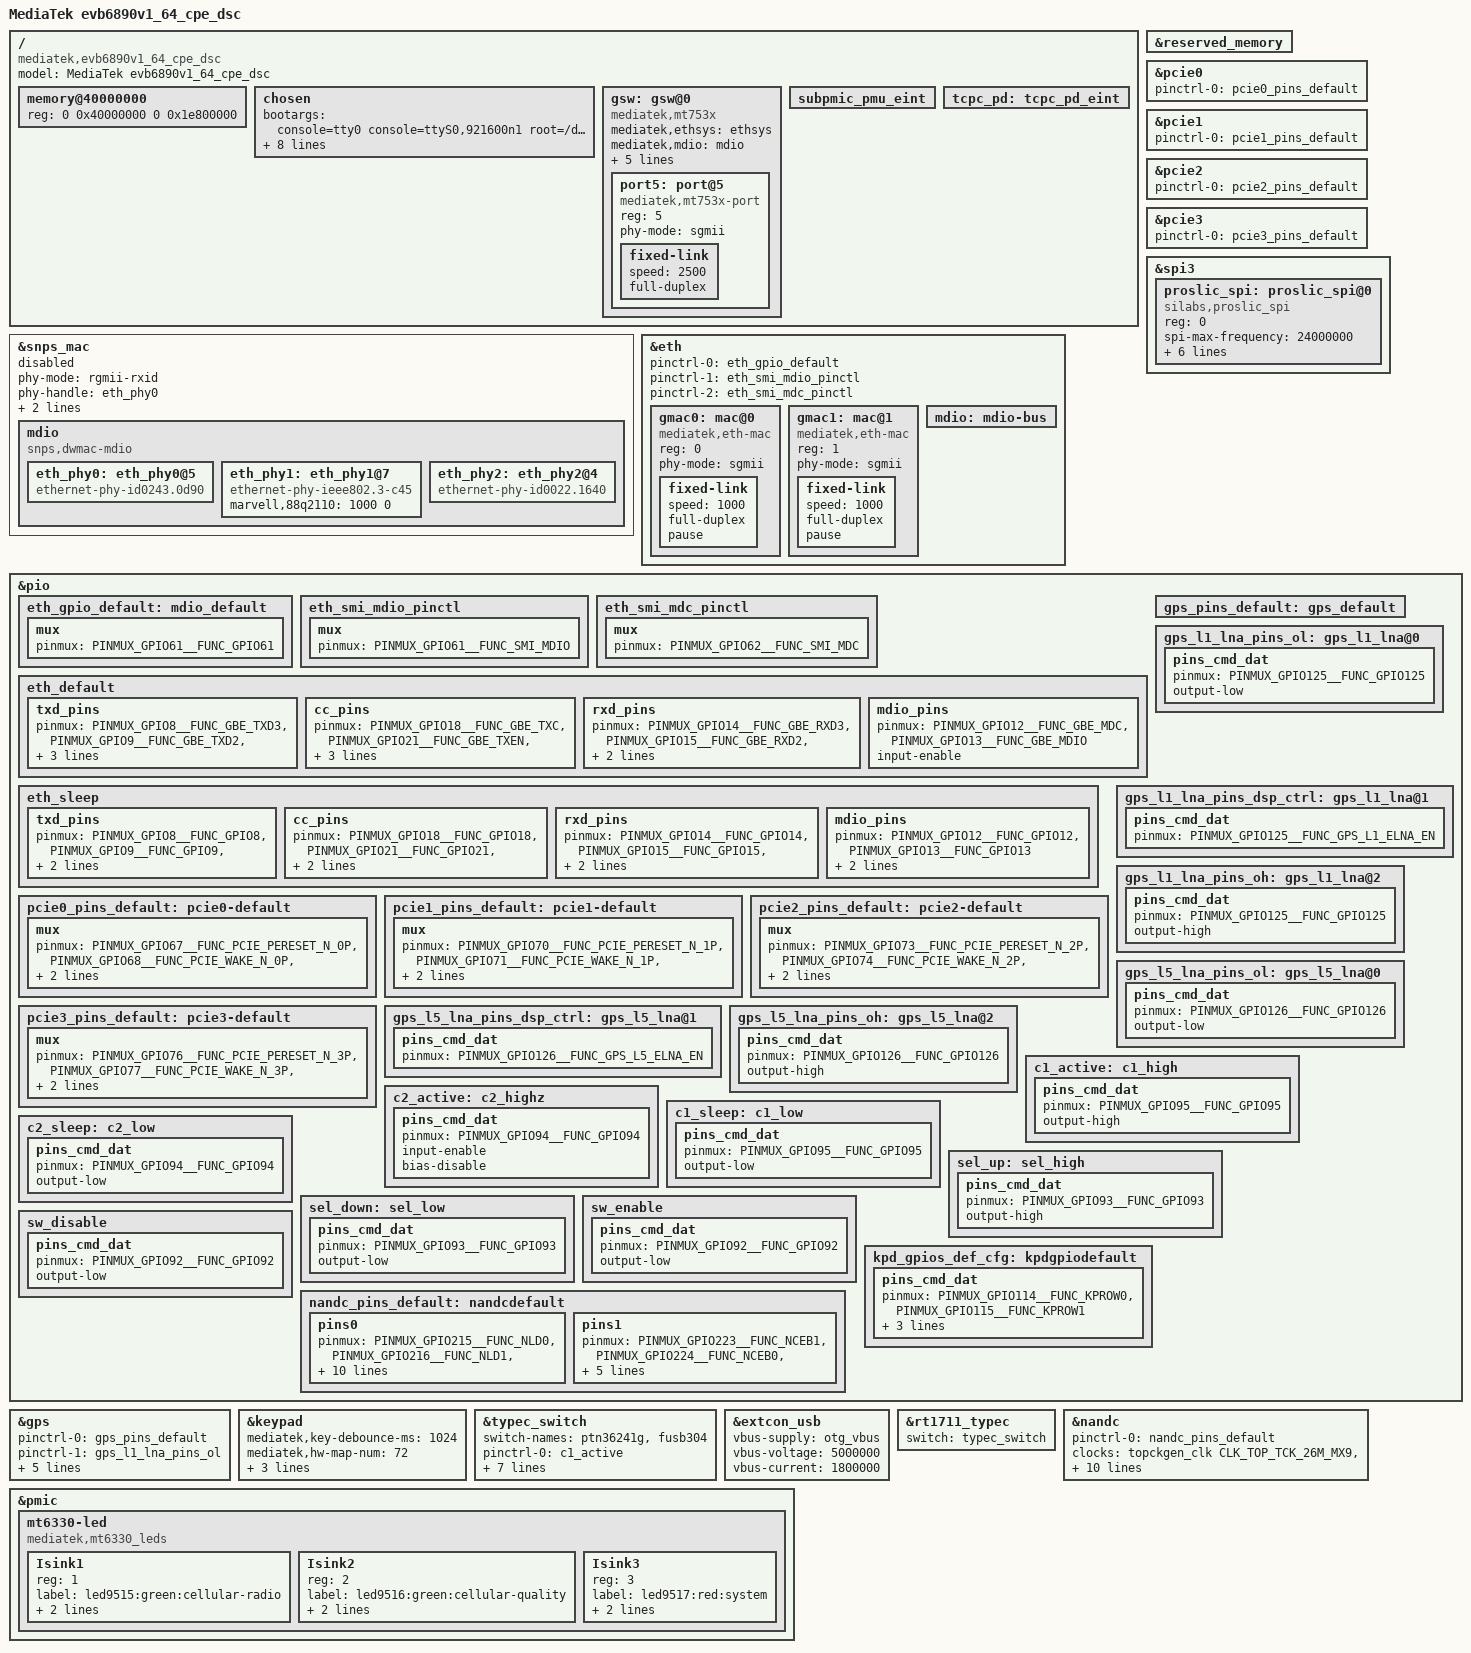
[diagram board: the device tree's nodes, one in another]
// SPDX-License-Identifier: GPL-2.0
/*
 * Copyright (c) 2019 MediaTek Inc.
 */

/dts-v1/;
#include <dt-bindings/interrupt-controller/irq.h>
#include <dt-bindings/interrupt-controller/arm-gic.h>
#include "mt6890.dtsi"
#include "tcpc_config.dtsi"
#include "rt9467.dtsi"

&reserved_memory {
};

/ {
	model = "MediaTek evb6890v1_64_cpe_dsc";
	compatible = "mediatek,evb6890v1_64_cpe_dsc", "mediatek,mt6890";

	memory@40000000 {
		device_type = "memory";
		reg = <0 0x40000000 0 0x1e800000>;
	};

	chosen {
		bootargs = "console=tty0 console=ttyS0,921600n1 \
		root=/dev/ubiblock0_0 rootfstype=squashfs ubi.mtd=28 \
		init=/etc/preinit \
		loglevel=8 \
		androidboot.selinux=permissive androidboot.hardware=mt6890 \
		initcall_debug=1";

		atag,videolfb-fb_base_l = <0x7e605000>;
		atag,videolfb-fb_base_h = <0x0>;
		atag,videolfb-islcmfound = <1>;
		atag,videolfb-islcm_inited = <0>;
		atag,videolfb-fps= <6000>;
		atag,videolfb-vramSize= <0x1be0000>;
		atag,videolfb-lcmname=
			"nt35595_fhd_dsi_cmd_truly_nt50358_drv";
	};

	gsw: gsw@0 {
		compatible = "mediatek,mt753x";
		mediatek,ethsys = <&ethsys>;
		#address-cells = <1>;
		#size-cells = <0>;
	};

	subpmic_pmu_eint: subpmic_pmu_eint {
	};

	tcpc_pd: tcpc_pd_eint {
	};
};

&snps_mac {
	phy-mode ="rgmii-rxid";
	phy-handle = <&eth_phy0>;
	status = "disable";
	pinctrl-names = "default", "sleep";
	pinctrl-0 = <&eth_default>;
	pinctrl-1 = <&eth_sleep>;
	mdio {
		compatible = "snps,dwmac-mdio";
		#address-cells = <1>;
		#size-cells = <0>;
		eth_phy0: eth_phy0@5 {
			compatible = "ethernet-phy-id0243.0d90";
		};
		eth_phy1: eth_phy1@7 {
			compatible = "ethernet-phy-ieee802.3-c45";
			marvell,88q2110 = <1000 0>;
		};
		eth_phy2: eth_phy2@4 {
			compatible = "ethernet-phy-id0022.1640";
		};
	};
};


&eth {
	pinctrl-names = "eth_gpio_default",
		"eth_smi_mdio_pinctl",
		"eth_smi_mdc_pinctl";
	pinctrl-0 = <&eth_gpio_default>;
	pinctrl-1 = <&eth_smi_mdio_pinctl>;
	pinctrl-2 = <&eth_smi_mdc_pinctl>;
	status = "okay";
	gmac0: mac@0 {
		compatible = "mediatek,eth-mac";
		reg = <0>;
		phy-mode = "sgmii";
		fixed-link {
			speed = <1000>;
			full-duplex;
			pause;
		};
	};
	gmac1: mac@1 {
		compatible = "mediatek,eth-mac";
		reg = <1>;
		phy-mode = "sgmii";
		fixed-link {
			speed = <1000>;
			full-duplex;
			pause;
		};
	};
	mdio: mdio-bus {
		#address-cells = <1>;
		#size-cells = <0>;
	};
};

&gsw {
	mediatek,mdio = <&mdio>;
	mediatek,portmap = "llllw";
	mediatek,mdio_master_pinmux = <0>;
	reset-gpios = <&pio 66 0>;
	interrupt-parent = <&pio>;
	interrupts = <65 IRQ_TYPE_LEVEL_HIGH>;

	status = "okay";

	port5: port@5 {
		compatible = "mediatek,mt753x-port";
		reg = <5>;
		phy-mode = "sgmii";
		fixed-link {
			speed = <2500>;
			full-duplex;
		};
	};
};

&pcie0 {
	pinctrl-names = "default";
	pinctrl-0 = <&pcie0_pins_default>;
	status = "okay";
};

&pcie1 {
	pinctrl-names = "default";
	pinctrl-0 = <&pcie1_pins_default>;
	status = "okay";
};

&pcie2 {
	pinctrl-names = "default";
	pinctrl-0 = <&pcie2_pins_default>;
	status = "okay";
};

&pcie3 {
	pinctrl-names = "default";
	pinctrl-0 = <&pcie3_pins_default>;
	status = "okay";
};

/*
&odm {
	vibrator0:vibrator@0 {
		compatible = "mediatek,vibrator";
		vib_timer = <25>;
		vib_limit = <9>;
		vib_vol= <9>;
	};
};*/

/* DISPSYS GPIO standardization */
#if 0
&pio {
	mtkfb_pins_lcd_bias_enp1: lcd_bias_enp1_gpio {
		pins_cmd_dat {
			pinmux = <PINMUX_GPIO28__FUNC_GPIO28>;
			slew-rate = <1>;
			output-high;
		};
	};

	mtkfb_pins_lcd_bias_enp0: lcd_bias_enp0_gpio {
		pins_cmd_dat {
			pinmux = <PINMUX_GPIO28__FUNC_GPIO28>;
			slew-rate = <1>;
			output-low;
		};
	};

	mtkfb_pins_lcd_bias_enn1: lcd_bias_enn1_gpio {
		pins_cmd_dat {
			pinmux = <PINMUX_GPIO29__FUNC_GPIO29>;
			slew-rate = <1>;
			output-high;
		};
	};

	mtkfb_pins_lcd_bias_enn0: lcd_bias_enn0_gpio {
		pins_cmd_dat {
			pinmux = <PINMUX_GPIO29__FUNC_GPIO29>;
			slew-rate = <1>;
			output-low;
		};
	};

	mtkfb_pins_lcm_rst_out1_gpio: lcm_rst_out1_gpio {
		pins_cmd_dat {
			pinmux = <PINMUX_GPIO42__FUNC_GPIO42>;
			slew-rate = <1>;
			output-high;
		};
	};

	mtkfb_pins_lcm_rst_out0_gpio: lcm_rst_out0_gpio {
		pins_cmd_dat {
			pinmux = <PINMUX_GPIO42__FUNC_GPIO42>;
			slew-rate = <1>;
			output-low;
		};
	};
	mtkfb_pins_lcm_dsi_te: lcm_dsi_te {
		pins_cmd_dat {
			pinmux = <PINMUX_GPIO41__FUNC_DSI_TE>;
		};
	};
};

&mtkfb {
	pinctrl-names = "lcd_bias_enp1_gpio", "lcd_bias_enp0_gpio",
		"lcd_bias_enn1_gpio", "lcd_bias_enn0_gpio",
		"lcm_rst_out1_gpio", "lcm_rst_out0_gpio",
		"mode_te_te";
	pinctrl-0 = <&mtkfb_pins_lcd_bias_enp1>;
	pinctrl-1 = <&mtkfb_pins_lcd_bias_enp0>;
	pinctrl-2 = <&mtkfb_pins_lcd_bias_enn1>;
	pinctrl-3 = <&mtkfb_pins_lcd_bias_enn0>;
	pinctrl-4 = <&mtkfb_pins_lcm_rst_out1_gpio>;
	pinctrl-5 = <&mtkfb_pins_lcm_rst_out0_gpio>;
	pinctrl-6 = <&mtkfb_pins_lcm_dsi_te>;
	status = "okay";
};
#endif

&spi3 {
	status = "okay";
	#address-cells=<1>;
	#size-cells=<0>;

	proslic_spi: proslic_spi@0 {
		compatible = "silabs,proslic_spi";
		reg = <0>;
		spi-max-frequency = <24000000>;
		spi-cpha = <1>;
		spi-cpol = <1>;
		channel_count = <1>;
		debug_level = <7>;       /* 1 = TRC, 2 = DBG, 4 = ERR */
		reset_gpio = <&pio 23 0>;       /* Hz */
		ig,enable-spi = <1>;                /* 1: Enable, 0: Disable */
	};
};
/* GPS GPIO standardization start */
#if 1
&pio {
	eth_gpio_default: mdio_default {
		mux {
			pinmux = <PINMUX_GPIO61__FUNC_GPIO61>;
		};
	};

	eth_smi_mdio_pinctl: eth_smi_mdio_pinctl {
		mux {
			pinmux = <PINMUX_GPIO61__FUNC_SMI_MDIO>;
		};
	};

	eth_smi_mdc_pinctl: eth_smi_mdc_pinctl {
		mux {
			pinmux = <PINMUX_GPIO62__FUNC_SMI_MDC>;
		};
	};

	eth_default: eth_default {
		txd_pins {
			pinmux = <PINMUX_GPIO8__FUNC_GBE_TXD3>,
				 <PINMUX_GPIO9__FUNC_GBE_TXD2>,
				 <PINMUX_GPIO10__FUNC_GBE_TXD1>,
				 <PINMUX_GPIO11__FUNC_GBE_TXD0>;
			drive-strength = <MTK_DRIVE_8mA>;
		};
		cc_pins {
			pinmux = <PINMUX_GPIO18__FUNC_GBE_TXC>,
				 <PINMUX_GPIO21__FUNC_GBE_TXEN>,
				 <PINMUX_GPIO20__FUNC_GBE_RXDV>,
				 <PINMUX_GPIO19__FUNC_GBE_RXC>;
			drive-strength = <MTK_DRIVE_8mA>;
		};
		rxd_pins {
			pinmux = <PINMUX_GPIO14__FUNC_GBE_RXD3>,
				 <PINMUX_GPIO15__FUNC_GBE_RXD2>,
				 <PINMUX_GPIO16__FUNC_GBE_RXD1>,
				 <PINMUX_GPIO17__FUNC_GBE_RXD0>;
		};
		mdio_pins {
			pinmux = <PINMUX_GPIO12__FUNC_GBE_MDC>,
				 <PINMUX_GPIO13__FUNC_GBE_MDIO>;
			input-enable;
		};
	};

	eth_sleep: eth_sleep {
		txd_pins {
			pinmux = <PINMUX_GPIO8__FUNC_GPIO8>,
				 <PINMUX_GPIO9__FUNC_GPIO9>,
				 <PINMUX_GPIO10__FUNC_GPIO10>,
				 <PINMUX_GPIO11__FUNC_GPIO11>;
		};
		cc_pins {
			pinmux = <PINMUX_GPIO18__FUNC_GPIO18>,
				 <PINMUX_GPIO21__FUNC_GPIO21>,
				 <PINMUX_GPIO20__FUNC_GPIO20>,
				 <PINMUX_GPIO19__FUNC_GPIO19>;
		};
		rxd_pins {
			pinmux = <PINMUX_GPIO14__FUNC_GPIO14>,
				 <PINMUX_GPIO15__FUNC_GPIO15>,
				 <PINMUX_GPIO16__FUNC_GPIO16>,
				 <PINMUX_GPIO17__FUNC_GPIO17>;
		};
		mdio_pins {
			pinmux = <PINMUX_GPIO12__FUNC_GPIO12>,
				 <PINMUX_GPIO13__FUNC_GPIO13>;
			input-disable;
			bias-disable;
		};
	};

	pcie0_pins_default: pcie0-default {
		mux {
			pinmux = <PINMUX_GPIO67__FUNC_PCIE_PERESET_N_0P>,
			         <PINMUX_GPIO68__FUNC_PCIE_WAKE_N_0P>,
				 <PINMUX_GPIO69__FUNC_PCIE_CLKREQ_N_0P>;
			bias-pull-up;
		};
	};

	pcie1_pins_default: pcie1-default {
		mux {
			pinmux = <PINMUX_GPIO70__FUNC_PCIE_PERESET_N_1P>,
			         <PINMUX_GPIO71__FUNC_PCIE_WAKE_N_1P>,
				 <PINMUX_GPIO72__FUNC_PCIE_CLKREQ_N_1P>;
			bias-pull-up;
		};
	};

	pcie2_pins_default: pcie2-default {
		mux {
			pinmux = <PINMUX_GPIO73__FUNC_PCIE_PERESET_N_2P>,
			         <PINMUX_GPIO74__FUNC_PCIE_WAKE_N_2P>,
				 <PINMUX_GPIO75__FUNC_PCIE_CLKREQ_N_2P>;
			bias-pull-up;
		};
	};

	pcie3_pins_default: pcie3-default {
		mux {
			pinmux = <PINMUX_GPIO76__FUNC_PCIE_PERESET_N_3P>,
			         <PINMUX_GPIO77__FUNC_PCIE_WAKE_N_3P>,
				 <PINMUX_GPIO78__FUNC_PCIE_CLKREQ_N_3P>;
			bias-pull-up;
		};
	};

	gps_pins_default: gps_default {
	};

	gps_l1_lna_pins_ol: gps_l1_lna@0 {
		pins_cmd_dat {
			pinmux = <PINMUX_GPIO125__FUNC_GPIO125>;
			output-low;
		};
	};
	gps_l1_lna_pins_dsp_ctrl: gps_l1_lna@1 {
		pins_cmd_dat {
			pinmux = <PINMUX_GPIO125__FUNC_GPS_L1_ELNA_EN>;
		};
	};
	gps_l1_lna_pins_oh: gps_l1_lna@2 {
		pins_cmd_dat {
			pinmux = <PINMUX_GPIO125__FUNC_GPIO125>;
			output-high;
		};
	};

	gps_l5_lna_pins_ol: gps_l5_lna@0 {
		pins_cmd_dat {
			pinmux = <PINMUX_GPIO126__FUNC_GPIO126>;
			output-low;
		};
	};
	gps_l5_lna_pins_dsp_ctrl: gps_l5_lna@1 {
		pins_cmd_dat {
			pinmux = <PINMUX_GPIO126__FUNC_GPS_L5_ELNA_EN>;
		};
	};
	gps_l5_lna_pins_oh: gps_l5_lna@2 {
		pins_cmd_dat {
			pinmux = <PINMUX_GPIO126__FUNC_GPIO126>;
			output-high;
		};
	};
};

&gps {
	pinctrl-names = "default",
		"gps_l1_lna_disable",
		"gps_l1_lna_dsp_ctrl",
		"gps_l1_lna_enable",
		"gps_l5_lna_disable",
		"gps_l5_lna_dsp_ctrl",
		"gps_l5_lna_enable";
	pinctrl-0 = <&gps_pins_default>;
	pinctrl-1 = <&gps_l1_lna_pins_ol>;
	pinctrl-2 = <&gps_l1_lna_pins_dsp_ctrl>;
	pinctrl-3 = <&gps_l1_lna_pins_oh>;
	pinctrl-4 = <&gps_l5_lna_pins_ol>;
	pinctrl-5 = <&gps_l5_lna_pins_dsp_ctrl>;
	pinctrl-6 = <&gps_l5_lna_pins_oh>;
	status = "okay";
};
#endif
/* GPS GPIO standardization end */

/* usb typec swtich */
&pio {
	c1_active: c1_high {
		pins_cmd_dat {
			pinmux = <PINMUX_GPIO95__FUNC_GPIO95>;
			output-high;
		};
	};

	c2_active: c2_highz {
		pins_cmd_dat {
			pinmux = <PINMUX_GPIO94__FUNC_GPIO94>;
			input-enable;
			bias-disable;
		};
	};

	c1_sleep: c1_low {
		pins_cmd_dat {
			pinmux = <PINMUX_GPIO95__FUNC_GPIO95>;
			output-low;
		};
	};

	c2_sleep: c2_low {
		pins_cmd_dat {
			pinmux = <PINMUX_GPIO94__FUNC_GPIO94>;
			output-low;
		};
	};

	sel_up: sel_high {
		pins_cmd_dat {
			pinmux = <PINMUX_GPIO93__FUNC_GPIO93>;
			output-high;
		};
	};

	sel_down: sel_low {
		pins_cmd_dat {
			pinmux = <PINMUX_GPIO93__FUNC_GPIO93>;
			output-low;
		};
	};

	sw_enable: sw_enable {
		pins_cmd_dat {
			pinmux = <PINMUX_GPIO92__FUNC_GPIO92>;
			output-low;
		};
	};

	sw_disable: sw_disable {
		pins_cmd_dat {
			pinmux = <PINMUX_GPIO92__FUNC_GPIO92>;
			output-low;
		};
	};
	kpd_gpios_def_cfg: kpdgpiodefault {
		pins_cmd_dat {
			pinmux = <PINMUX_GPIO114__FUNC_KPROW0>,
				<PINMUX_GPIO115__FUNC_KPROW1>;
			mediatek,pull-down-adv = <MTK_PUPD_SET_R1R0_01>;
			output-low;
			input-schmitt-enable;
		};
	};
};

&keypad {
	mediatek,key-debounce-ms = <1024>;
	/*HW Keycode [0~71] -> Linux Keycode*/
	mediatek,hw-map-num = <72>;
	mediatek,hw-init-map = <0 0 114 0 0 0 0 0 0 0 0 0 0 0 0 115 0 0 0 0 0 0 0
		0 0 0 0 0 112 0 0 0 0 0 0 0 0 0 0 0 0 0 0 0 0 0 0 0 0 0 0 0 0 0 0
		0 0 0 0 0 0 0 0 0 0 0 0 0 0 0 0 0 >;
	status = "okay";
	pinctrl-names = "default";
	pinctrl-0 = <&kpd_gpios_def_cfg>;
};

&typec_switch {
	switch-names = "ptn36241g","fusb304";
	pinctrl-names = "c1_active", "c1_sleep",
		"c2_active", "c2_sleep",
		"sel_up", "sel_down",
		"enable", "disable";
	/* ptn36241g */
	pinctrl-0 = <&c1_active>;
	pinctrl-1 = <&c1_sleep>;
	pinctrl-2 = <&c2_active>;
	pinctrl-3 = <&c2_sleep>;
	/* fusb304 */
	pinctrl-4 = <&sel_up>;
	pinctrl-5 = <&sel_down>;
	pinctrl-6 = <&sw_enable>;
	pinctrl-7 = <&sw_disable>;
};

&extcon_usb {
	vbus-supply = <&otg_vbus>;
	vbus-voltage = <5000000>;
	vbus-current = <1800000>;
};

&rt1711_typec {
	switch = <&typec_switch>;
};

&pio {
	nandc_pins_default: nandcdefault {
		pins0 {
			pinmux = <PINMUX_GPIO215__FUNC_NLD0>,
				<PINMUX_GPIO216__FUNC_NLD1>,
				<PINMUX_GPIO217__FUNC_NLD2>,
				<PINMUX_GPIO218__FUNC_NLD3>,
				<PINMUX_GPIO219__FUNC_NLD4>,
				<PINMUX_GPIO220__FUNC_NLD5>,
				<PINMUX_GPIO221__FUNC_NLD6>,
				<PINMUX_GPIO222__FUNC_NLD7>,
				<PINMUX_GPIO228__FUNC_NALE>,
				<PINMUX_GPIO229__FUNC_NCLE>;
			drive-strength = <MTK_DRIVE_4mA>;
			bias-pull-down;
		};
		pins1 {
			pinmux = <PINMUX_GPIO223__FUNC_NCEB1>,
				<PINMUX_GPIO224__FUNC_NCEB0>,
				<PINMUX_GPIO225__FUNC_NRNB>,
				<PINMUX_GPIO226__FUNC_NREB>,
				<PINMUX_GPIO227__FUNC_NWEB>;
			drive-strength = <MTK_DRIVE_4mA>;
			bias-pull-up;
		};
	};
};

&nandc {
	status = "okay";
	pinctrl-names = "default";
	pinctrl-0 = <&nandc_pins_default>;
	clocks =<&topckgen_clk CLK_TOP_TCK_26M_MX9>,
			<&topckgen_clk CLK_TOP_UNIVPLL_D5_D4>,
			<&topckgen_clk CLK_TOP_MAINPLL_D7_D4>,
			<&topckgen_clk CLK_TOP_MAINPLL_D6_D4>,
			<&topckgen_clk CLK_TOP_UNIVPLL_D6_D4>,
			<&topckgen_clk CLK_TOP_MAINPLL_D4_D4>,
			<&topckgen_clk CLK_TOP_UNIVPLL_D4_D4>,
			<&topckgen_clk CLK_TOP_MAINPLL_D6_D2>,
			<&topckgen_clk CLK_TOP_NFI1X_SEL>,
			<&infracfg_ao_clk CLK_IFRAO_RG_66M_NFI_HCLK_CK>,
			<&infracfg_ao_clk CLK_IFRAO_RG_NFI>;
	clock-names = "nfi_parent_26m",
			"nfi_parent124.8m",
			"nfi_parent78m",
			"nfi_parent91m",
			"nfi_parent104m",
			"nfi_parent136.5m",
			"nfi_parent156m",
			"nfi_parent182m",
			"nfi_clk_sel",
			"dma_cg",
			"nfi_cg";
};

/*************************
 * PMIC LED DTSI File
*************************/
&pmic {
	mt6330-led {
		compatible = "mediatek,mt6330_leds";
		Isink1 {
			reg = <1>;
			label = "led9515:green:cellular-radio";
			linux,default-trigger = "none";
			default-state = "off";
		};
		Isink2 {
			reg = <2>;
			label = "led9516:green:cellular-quality";
			linux,default-trigger = "none";
			default-state = "off";
		};
		Isink3 {
			reg = <3>;
			label = "led9517:red:system";
			linux,default-trigger = "none";
			default-state = "off";
		};
	};
};

#include <mediatek/evb6890v1_64_cpe_dsc/cust.dtsi>
/*End of this file, DO NOT ADD ANYTHING HERE*/
